# nrf9230_enga_cellrf register map
Vendor: Nordic Semiconductor; Series: nRF92; File version: 1
CPU: CM0 r0p0, little endian, no MPU, no FPU, 2 interrupt priority bits, 33 interrupts
Registers are 32-bit, read-write, reset 0x0 unless marked. A register's access mark holds for its fields unless they carry their own. Offsets are from the block's base; [hi:lo] are bit positions; lines under a group give offsets from that group; {n}, {i} and the like mark numbered series; 'fields as' and 'values as' point back to an identical list.

## RFTIMERTX — RfTimer 0
Base 0x46021000
Same registers: RFTIMERRX 0x46032000, RFTIMERSTC 0x46048000
0x00 TASKS_START wo — Start timer
  [0] TASKS_START
    1=Trigger task
0x04 TASKS_STOP wo — Stop timer
  [0] TASKS_STOP
    1=Trigger task
0x08 TASKS_CLEAR wo — Clear timer
  [0] TASKS_CLEAR
    1=Trigger task
0x0C TASKS_SHUTDOWN wo — Shut down timer
  [0] TASKS_SHUTDOWN
    1=Trigger task
0x10 TASKS_STANDBY wo — Standby timer
  [0] TASKS_STANDBY
    1=Trigger task
{0x14+4i} TASKS_CAPTURE[{i}] (i=0..15) wo — Description collection: Capture Timer value to CC[n] register
  [0] TASKS_CAPTURE — Capture Timer value to CC[n] register
    1=Trigger task
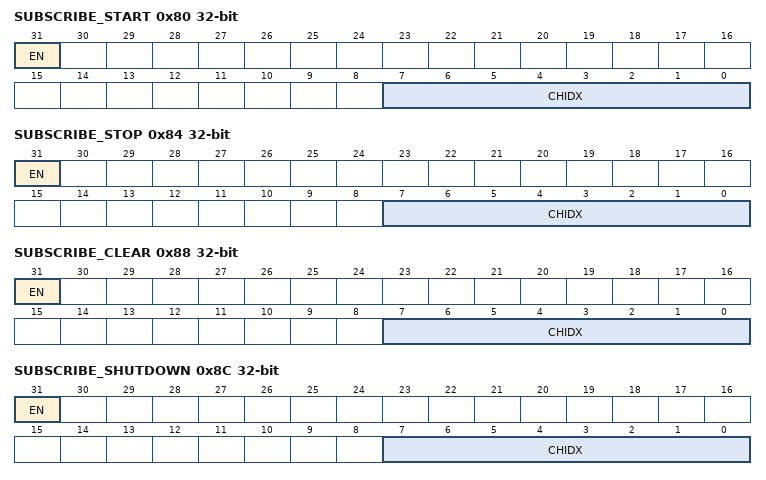
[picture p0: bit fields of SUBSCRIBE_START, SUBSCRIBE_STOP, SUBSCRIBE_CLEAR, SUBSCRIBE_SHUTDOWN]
0x80 SUBSCRIBE_START — Subscribe configuration for task START
  [31] EN
    0=Disabled (Disable subscription); 1=Enabled (Enable subscription)
  [7:0] CHIDX — DPPI channel that task START will subscribe to
0x84 SUBSCRIBE_STOP — Subscribe configuration for task STOP
  [31] EN
    values as SUBSCRIBE_START.EN
  [7:0] CHIDX — DPPI channel that task STOP will subscribe to
0x88 SUBSCRIBE_CLEAR — Subscribe configuration for task CLEAR
  [31] EN
    values as SUBSCRIBE_START.EN
  [7:0] CHIDX — DPPI channel that task CLEAR will subscribe to
0x8C SUBSCRIBE_SHUTDOWN — Subscribe configuration for task SHUTDOWN
  [31] EN
    values as SUBSCRIBE_START.EN
  [7:0] CHIDX — DPPI channel that task SHUTDOWN will subscribe to
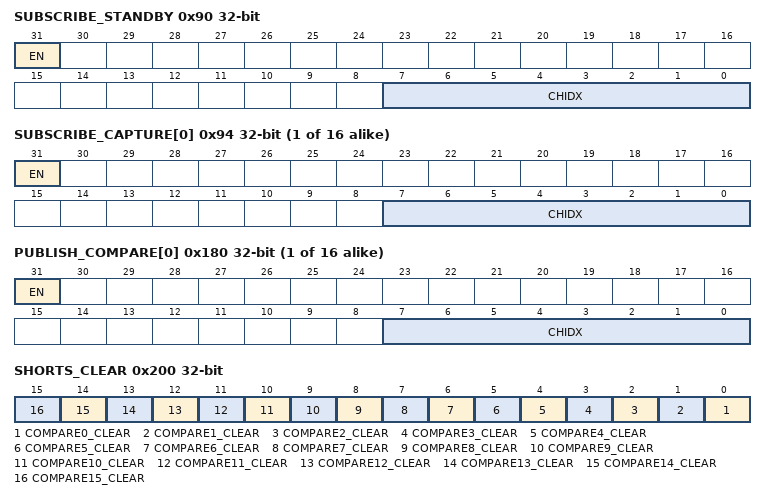
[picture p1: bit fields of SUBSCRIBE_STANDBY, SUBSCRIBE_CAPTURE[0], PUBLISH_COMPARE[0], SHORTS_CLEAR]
0x90 SUBSCRIBE_STANDBY — Subscribe configuration for task STANDBY
  [31] EN
    values as SUBSCRIBE_START.EN
  [7:0] CHIDX — DPPI channel that task STANDBY will subscribe to
{0x94+4i} SUBSCRIBE_CAPTURE[{i}] (i=0..15) — Description collection: Subscribe configuration for task CAPTURE[n]
  [31] EN
    values as SUBSCRIBE_START.EN
  [7:0] CHIDX — DPPI channel that task CAPTURE[n] will subscribe to
{0x100+4i} EVENTS_COMPARE[{i}] (i=0..15) — Description collection: Compare event on CC[n] match
  [0] EVENTS_COMPARE — Compare event on CC[n] match
    0=NotGenerated (Event not generated); 1=Generated (Event generated)
{0x180+4i} PUBLISH_COMPARE[{i}] (i=0..15) — Description collection: Publish configuration for event COMPARE[n]
  [31] EN
    0=Disabled (Disable publishing); 1=Enabled (Enable publishing)
  [7:0] CHIDX — DPPI channel that event COMPARE[n] will publish to
0x200 SHORTS_CLEAR — Shortcuts between local events and tasks
  [all] fields
    0=Disabled (Disable shortcut); 1=Enabled (Enable shortcut)
  [n] COMPARE{n}_CLEAR (n=0..15) — Shortcuts between events COMPARE[{n}] and task CLEAR
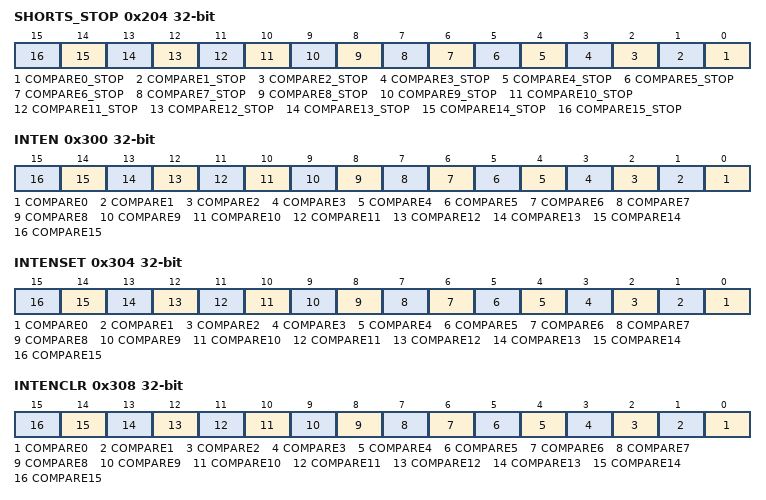
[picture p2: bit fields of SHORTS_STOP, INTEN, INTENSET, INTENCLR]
0x204 SHORTS_STOP — Shortcuts between local events and tasks
  [all] fields
    0=Disabled (Disable shortcut); 1=Enabled (Enable shortcut)
  [n] COMPARE{n}_STOP (n=0..15) — Shortcuts between events COMPARE[{n}] and task STOP
0x300 INTEN — Enable or disable interrupt
  [all] fields
    0=Disabled; 1=Enabled
  [n] COMPARE{n} (n=0..15) — Enable or disable interrupt for event COMPARE[{n}]
0x304 INTENSET — Enable interrupt
  [all] fields
    on read: 0=Disabled (Read: Disabled); 1=Enabled (Read: Enabled) | on write: 1=Set (Enable)
  [n] COMPARE{n} (n=0..15) — Write '1' to enable interrupt for event COMPARE[{n}]
0x308 INTENCLR — Disable interrupt
  [all] fields
    on read: 0=Disabled (Read: Disabled); 1=Enabled (Read: Enabled) | on write: 1=Clear (Disable)
  [n] COMPARE{n} (n=0..15) — Write '1' to disable interrupt for event COMPARE[{n}]
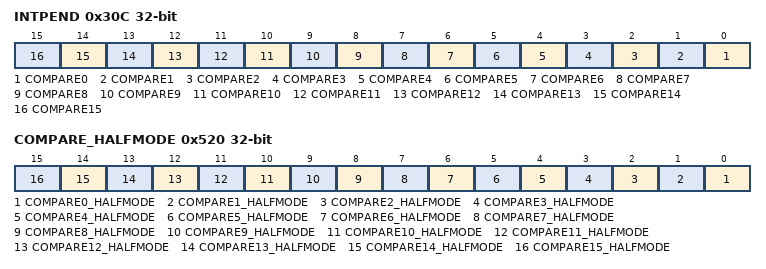
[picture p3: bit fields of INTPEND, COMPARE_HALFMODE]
0x30C INTPEND ro — Pending interrupts
  [all] fields
    on read: 0=NotPending (Read: Not pending); 1=Pending (Read: Pending)
  [n] COMPARE{n} (n=0..15) — Read pending status of interrupt for event COMPARE[{n}]
0x500 ENABLE — Enable the RFTIMER.
  [0] ENABLE — Enable or disable RFTIMER, when enabled the synchronous reset of core is not requested in shutdown state.
    0=Disabled (Disable RFTIMER); 1=Enabled (Enable RFTIMER)
0x504 STATUS ro — Status of RFTIMER
  [1:0] STATUS — Timer status
    0=SHUTDOWN (RfTimer is powered off); 1=STARTED (RfTimer is started and it is running); 2=STOPPED (RfTimer is stopped)
0x520 COMPARE_HALFMODE — Compare half mode selection.
  [all] fields
    0=Disabled; 1=Enabled
  [n] COMPARE{n}_HALFMODE (n=0..15) — Enable half mode COMPARE[{n}]
{0x540+8i} CC[{i}] (i=0..15) group — Unspecified
  0x00 LO reset 0xFFFFFFFF — Description cluster: Capture/Compare[n] Low Word register
    [31:0] CC_LO — Capture/Compare Low Word value
  0x04 HI reset 0xFFFFFFFF — Description cluster: Capture/Compare[n] High Word register
    [31:0] CC_HI — Capture/Compare High Word value
